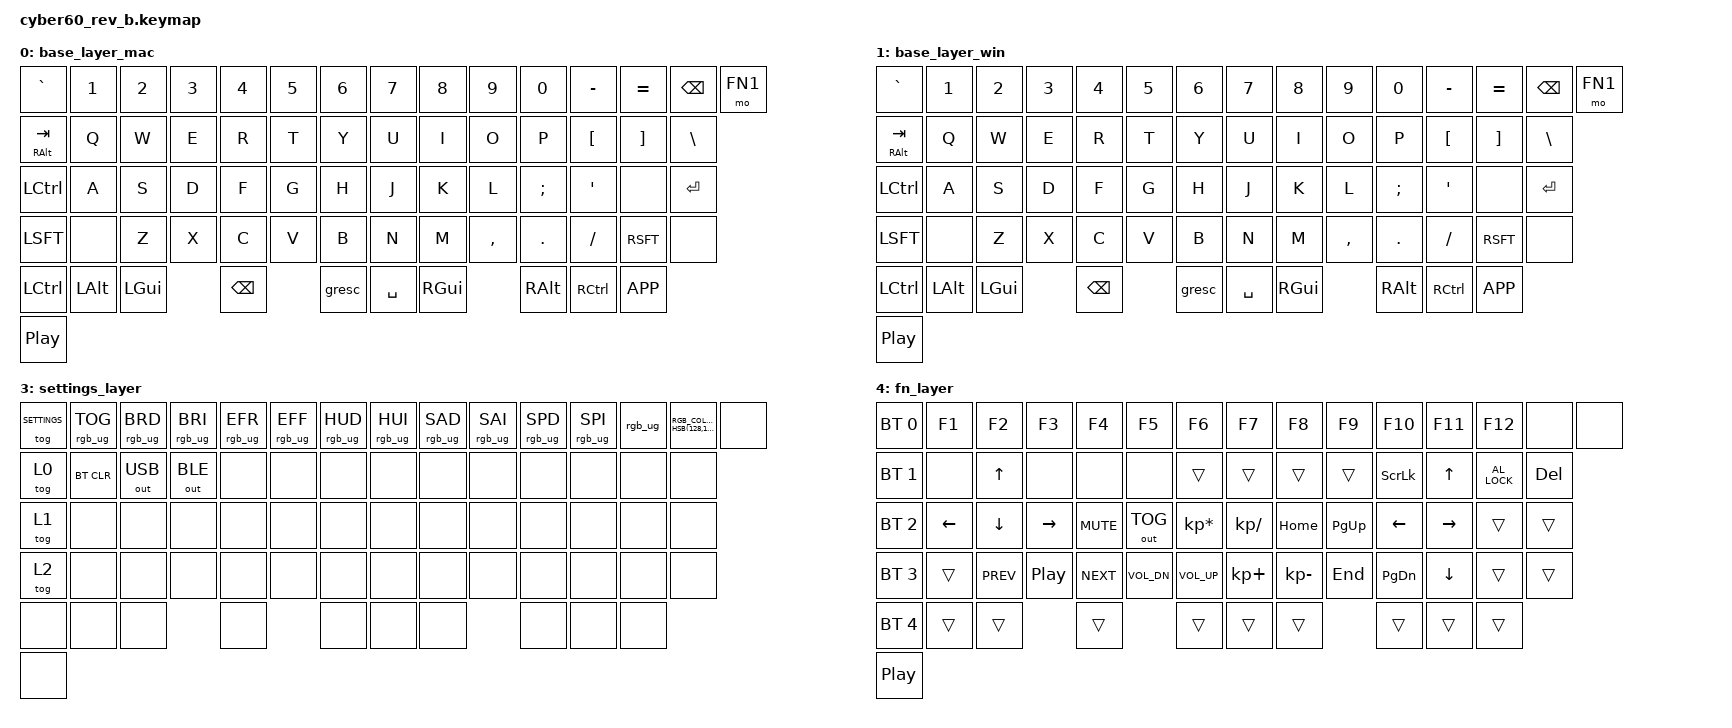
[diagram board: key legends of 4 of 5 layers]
#include <behaviors.dtsi>
#include <dt-bindings/zmk/keys.h>
#include <dt-bindings/zmk/bt.h>
#include <dt-bindings/zmk/outputs.h>
#include <dt-bindings/zmk/rgb.h>
#include <dt-bindings/zmk/ext_power.h>


#define FN1 4
#define SETTINGS 3
/ {
	keymap {
		compatible = "zmk,keymap";
		base_layer_mac {
// Base layer with gui at backspace position
// ------------------------------------------------------------------------------------------
// | ~ |  1  |  2  |  3  |  4  |  5  |  6  |  7  |  8  |  9  |  0  |  -  |  =  | BKSP | FN  |
// |RALT/TAB| Q |  W  |  E  |  R  |  T  |  Y  |  U  |  I  |  O  |  P  |  [  |  ]  |   "|"   |
// | LCTL  |  A  |  S  |  D  |  F  |  G  |  H  |  J  |  K  |  L  |  ;  |  '  |none|  ENTER  |
// | SHIFT |none| Z |  X  |  C  |  V  |  B  |  N  |  M  |  ,  |  .  |  /  |    Shift   | FN |
// |  LCTL  |  LALT  |  LWIN  |  BKSP | ESC |     SPACE     |  RWIN |  RALT | RCTRL | RMENU |
// | Rotary | (<-- Rotary switch) -----------------------------------------------------------
			bindings = <
	&kp GRAV	 &kp NUM_1 	&kp NUM_2	&kp NUM_3 	&kp NUM_4 &kp NUM_5 &kp NUM_6 	&kp NUM_7 	&kp NUM_8 &kp NUM_9	&kp NUM_0	&kp MINUS	&kp EQL		&kp BKSP	&mo FN1
	&mt RALT TAB &kp   Q   	&kp   W   	&kp   E   	&kp   R   &kp   T   &kp   Y   	&kp   U   	&kp   I   &kp   O   &kp   P   	&kp LBKT 	&kp RBKT	&kp BSLH
	&kp LCTL 	 &kp   A   	&kp   S   	&kp   D   	&kp   F   &kp   G   &kp   H   	&kp   J   	&kp   K   &kp   L   &kp  SCLN  	&kp  QUOT   &none		&kp RET
	&kp LSFT 	 &none		&kp   Z   	&kp   X   	&kp   C   &kp   V   &kp   B   	&kp   N   	&kp   M   &kp  CMMA &kp  DOT  	&kp  FSLH	&kp RSFT 	&none
	&kp LCTL 	 &kp LALT   &kp LGUI				&kp BKSP			&gresc		&kp  SPC  	&kp  RGUI			&kp  RALT 	&kp RCTL	&kp  K_APP
	&kp C_PP
			>;
			sensor-bindings = <&inc_dec_kp C_VOL_DN C_VOL_UP>;
		};
		base_layer_win {
// Base layer with gui at backspace position
// ------------------------------------------------------------------------------------------
// | ~ |  1  |  2  |  3  |  4  |  5  |  6  |  7  |  8  |  9  |  0  |  -  |  =  | BKSP | FN  |
// |RALT/TAB| Q |  W  |  E  |  R  |  T  |  Y  |  U  |  I  |  O  |  P  |  [  |  ]  |   "|"   |
// | LCTL  |  A  |  S  |  D  |  F  |  G  |  H  |  J  |  K  |  L  |  ;  |  '  |none|  ENTER  |
// | SHIFT |none| Z |  X  |  C  |  V  |  B  |  N  |  M  |  ,  |  .  |  /  |    Shift   | FN |
// |  LCTL  |  LALT  |  LWIN  |  BKSP | ESC |     SPACE     |  RWIN |  RALT | RCTRL | RMENU |
// | Rotary | (<-- Rotary switch) -----------------------------------------------------------
			bindings = <
	&kp GRAV	 &kp NUM_1 	&kp NUM_2	&kp NUM_3 	&kp NUM_4 &kp NUM_5 &kp NUM_6 	&kp NUM_7 	&kp NUM_8 &kp NUM_9	&kp NUM_0	&kp MINUS	&kp EQL		&kp BKSP	&mo FN1
	&mt RALT TAB &kp   Q   	&kp   W   	&kp   E   	&kp   R   &kp   T   &kp   Y   	&kp   U   	&kp   I   &kp   O   &kp   P   	&kp LBKT 	&kp RBKT	&kp BSLH
	&kp LCTL 	 &kp   A   	&kp   S   	&kp   D   	&kp   F   &kp   G   &kp   H   	&kp   J   	&kp   K   &kp   L   &kp  SCLN  	&kp  QUOT   &none		&kp RET
	&kp LSFT 	 &none		&kp   Z   	&kp   X   	&kp   C   &kp   V   &kp   B   	&kp   N   	&kp   M   &kp  CMMA &kp  DOT  	&kp  FSLH	&kp RSFT 	&none
	&kp LCTL 	 &kp LALT   &kp LGUI				&kp BKSP			&gresc		&kp  SPC  	&kp  RGUI			&kp  RALT 	&kp RCTL	&kp  K_APP
	&kp C_PP
			>;
			sensor-bindings = <&inc_dec_kp C_VOL_DN C_VOL_UP>;
		};
		gaming_layer {
// Gaming layer with regular space and no gui
// ------------------------------------------------------------------------------------------
// | ESC |  1  |  2  |  3  |  4  |  5  |  6  |  7  |  8  |  9  |  0  |  -  |  =  | "|" |  ~ |
// |  TAB |  Q  |  W  |  E  |  R  |  T  |  Y  |  U  |  I  |  O  |  P  |  [  |  ]  |   BKSP  |
// | LCTL  |  A  |  S  |  D  |  F  |  G  |  H  |  J  |  K  |  L  |  ;  |  '  |none| ENTER   |
// | SHIFT |none| Z |  X  |  C  |  V  |  B  |  N  |  M  |  ,  |  .  |  /  |    Shift   | FN |
// |  LCTL  |  NONE  |  LALT  | SPACE  | FN |     SPACE     |  RALT |  RWIN | RMENU | RCTRL |
// | Rotary | (<-- Rotary switch) -----------------------------------------------------------
				bindings = <
	&trans &trans &trans &trans &trans &trans &trans &trans &trans &trans &trans &trans &trans &trans
	&trans &trans &trans &trans &trans &trans &trans &trans &trans &trans &trans &trans &trans &kp BKSP
	&trans &trans &trans &trans &trans &trans &trans &trans &trans &trans &trans &trans &trans &trans
	&trans &trans &trans &trans &trans &trans &trans &trans &trans &trans &trans &trans &trans &trans
	&trans &trans &trans &kp SPC &trans &trans &trans &trans &trans &trans
	&kp C_PP
			>;
			sensor-bindings = <&inc_dec_kp C_VOL_DN C_VOL_UP>;
		};
		settings_layer {
// Settings layer to change keyboard behaviour
// ------------------------------------------------------------------------------------------
// | EXIT|BOOTL| RST | USB | BLE | NON | NON | NON | NON | NON | NON | NON | NON | NON |NON |
// | NON  |BTCLR| BT0 | BT1 | BT2 | BT3 | BT4 | NON | NON | NON | NON | NON | NON |   NON   |
// |  NON  | TOG0| TOG1| TOG2| TOG3| NON | NON | NON | NON | NON | NON | NON | NON |  NON   |
// |  NON | NON |NON| NON | NON | NON | NON | NON | NON | NON | NON | NON |    NON    | NON |
// |   NON  |  NON   |  NON   |   NON  | NON |    NON       |  NON  |  NON  |  NON  |  NON  |
// | Rotary | (<-- Rotary switch) -----------------------------------------------------------
				bindings = <
	&tog SETTINGS &rgb_ug RGB_TOG &rgb_ug RGB_BRD	&rgb_ug RGB_BRI &rgb_ug RGB_EFR &rgb_ug  RGB_EFF	&rgb_ug RGB_HUD	&rgb_ug RGB_HUI	&rgb_ug RGB_SAD	&rgb_ug RGB_SAI	&rgb_ug RGB_SPD	&rgb_ug RGB_SPI	&rgb_ug RGB_COLOR_HSB(128,100,100) &none
	&tog 0 &bt BT_CLR &out OUT_USB &out OUT_BLE &none &none &none &none &none &none &none &none &none &none
	&tog 1 &none &none &none &none &none &none &none &none &none &none &none &none &none
	&tog 2 &none &none &none &none &none &none &none &none &none &none &none &none &none
	&none &none &none &none &none &none &none &none &none &none
	&none
			>;
			sensor-bindings = <&inc_dec_kp C_VOL_DN C_VOL_UP>;
		};
		fn_layer {
// Function layer
// ------------------------------------------------------------------------------------------
// | NON  |  F1 |  F2 |  F3 |  F4 |  F5 |  F6 |  F7 |  F8 |  F9 | F10 | F11 | F12 |NON | NON|
// | TAB  |BTPRV|  UP |BTNXT| TOG0| TOG1| TOG2| BT3 | BT4 | PRNT| SLCKL | UP  | LOCK |  DEL |
// | CAPS  |LEFT |DOWN |RIGHT|MUTE | OUT_TOG | * | / | HOME| PGUP| LEFT|RIGHT|none|  ENTER  |
// | SHIFT |none|PRV|PLAYP|NEXT | VOLD| VOLU|  +  |  -  | END | PGDN| DOWN|    Shift   | FN |
// |  LCTL  |  LGUI  |  LWIN  |  RALT  | FN |     SPACE     |  RALT |  RWIN | RMENU | RCTRL |
// | Rotary | (<-- Rotary switch) -----------------------------------------------------------
			bindings = <
	&bt BT_SEL 0  &kp F1 &kp F2 &kp F3 &kp F4 &kp F5 &kp F6 &kp F7 &kp F8 &kp F9 &kp F10 &kp F11 &kp F12 &none &none
	&bt BT_SEL 1  &none   &kp UP  &none		&none   &none  &trans			&trans			&trans			&trans			&kp SLCK	&kp UP		&kp C_AL_LOCK	&kp DEL
	&bt BT_SEL 2  &kp LEFT   	&kp DOWN		&kp RIGHT		&kp K_MUTE		&out OUT_TOG			&kp KP_ASTERISK	&kp KP_SLASH	&kp HOME		&kp PG_UP		&kp LEFT	&kp RIGHT	&trans		&trans
	&bt BT_SEL 3  &trans &kp C_PREV &kp C_PP	 	&kp C_NEXT 		&kp C_VOL_DN	&kp C_VOL_UP	&kp KP_PLUS		&kp KP_MINUS	&kp END			&kp PG_DN	&kp DOWN	&trans 		&trans
	&bt BT_SEL 4  &trans &trans &trans &trans &trans &trans &trans &trans &trans
	&kp C_PP
			>;
			sensor-bindings = <&inc_dec_kp C_VOL_DN C_VOL_UP>;
		};
	};
};
